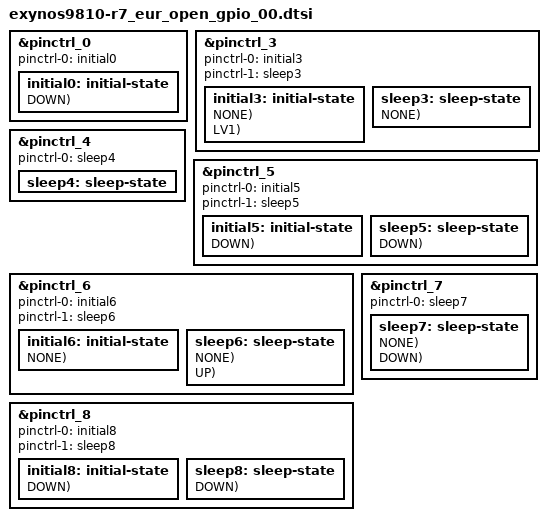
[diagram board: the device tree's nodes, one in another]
/*
 * Copyright (c) 2016 Samsung Electronics Co., Ltd.
 *		http://www.samsung.com
 *
 * This program is free software; you can redistribute it and/or modify
 * it under the terms of the GNU General Public License version 2 as
 * published by the Free Software Foundation.
 */

// Support R7 EUR HW REV0.0 (0 0000)

#include "exynos_gpio_config_macros.dtsi"

/*
 * pin banks of exynos9810 pin-controller 0 (ALIVE)
 * ETC1
 * GPA0 GPA1 GPA2 GPA3
 * GPQ0
 * GPA4
 * Note that do not set sleep state because GPA0/1/2/3/4, GPQ0 and ETC1 are in
 * ALIVE region.
 */
&pinctrl_0 {
	pinctrl-names = "default";
	pinctrl-0 = <&initial0>;
	initial0: initial-state {
		PIN_IN(gpq0-5, DOWN);	/* NC */
	};
};

/*
 * pin banks of exynos9810 pin-controller 1 (AUD)
 * GPB0 GPB1 GPB2
 * Do not set!! Audio block is very sensitive!!
 */

/*
 * pin banks of exynos9810 pin-controller 3 (CMGP)
 * GPM0 GPM1 GPM2 GPM3 GPM4 GPM5 GPM6 GPM7
 * GPM10 GPM11 GPM12 GPM13 GPM14 GPM15 GPM16 GPM17
 * GPM40 GPM41 GPM42 GPM43
 */
&pinctrl_3 {
	pinctrl-names = "default","sleep";
	pinctrl-0 = <&initial3>;
	pinctrl-1 = <&sleep3>;
	initial3: initial-state {
		PIN_FUNC(gpm4-0, 2, NONE);	/* SHUB_CP_TXD */
		PIN_FUNC(gpm5-0, 2, NONE);	/* SHUB_CP_RXD */
		PIN_OUT_SET(gpm42-0, 1, LV1);    /* SPEN_LDO_EN */
	};
	sleep3: sleep-state {
		PIN_SLP(gpm42-0, PREV, NONE);    /* SPEN_LDO_EN */
	};
};

/*
 * pin banks of exynos9810 pin-controller 4 (FSYS0)
 * GPF0
 */
&pinctrl_4 {
	pinctrl-names = "sleep";
	pinctrl-0 = <&sleep4>;
	sleep4: sleep-state {

	};
};

/*
 * pin banks of exynos9810 pin-controller 5 (FSYS1)
 * GPF1 GPF2
 */
&pinctrl_5 {
	pinctrl-names = "default","sleep";
	pinctrl-0 = <&initial5>;
	pinctrl-1 = <&sleep5>;
	initial5: initial-state {
		PIN_IN(gpf2-1, DOWN);		/* NC */
		PIN_IN(gpf2-4, DOWN);		/* NC */
	};
	sleep5: sleep-state {
		PIN_SLP(gpf2-1, INPUT, DOWN);	/* NC */
		PIN_SLP(gpf2-4, INPUT, DOWN);	/* NC */
	};
};

/*
 * pin banks of exynos9810 pin-controller 6 (PERIC0)
 * GPP0 GPP1 GPP2 GPP3
 * GPG0 GPG1 GPG2
 */
&pinctrl_6 {
	pinctrl-names = "default","sleep";
	pinctrl-0 = <&initial6>;
	pinctrl-1 = <&sleep6>;
	initial6: initial-state {
		PIN_IN(gpp2-4, NONE);	/* MEM_SCL_1P8 */
		PIN_IN(gpp2-5, NONE);	/* MEM_SDA_1P8 */

		PIN_IN(gpg1-1, NONE);	/* HW_REV_M */
		PIN_IN(gpg1-2, NONE);	/* HW_REV3 */
		PIN_IN(gpg1-3, NONE);	/* HW_REV2 */
		PIN_IN(gpg1-4, NONE);	/* HW_REV1 */
		PIN_IN(gpg1-5, NONE);	/* HW_REV0 */
	};
	sleep6: sleep-state {
		PIN_SLP(gpp2-4, INPUT, NONE);	/* MEM_SCL_1P8 */
		PIN_SLP(gpp2-5, INPUT, NONE);	/* MEM_SDA_1P8 */

		PIN_SLP(gpp1-4, PREV, NONE);	/* TSP_SCL_1P8 */
		PIN_SLP(gpp1-5, PREV, NONE);	/* TSP_SDA_1P8 */

		PIN_SLP(gpg0-0, INPUT, UP);	/* FG_ALERT_N */
		PIN_SLP(gpg0-3, INPUT, NONE);	/* SMPL_WARN_AP */

		PIN_SLP(gpg1-1, INPUT, NONE);	/* HW_REV_M */
		PIN_SLP(gpg1-2, INPUT, NONE);	/* HW_REV3 */
		PIN_SLP(gpg1-3, INPUT, NONE);	/* HW_REV2 */
		PIN_SLP(gpg1-4, INPUT, NONE);	/* HW_REV1 */
		PIN_SLP(gpg1-5, INPUT, NONE);	/* HW_REV0 */

		PIN_SLP(gpg1-7, PREV, NONE);	/* DC_IRQ_N */

		PIN_SLP(gpg2-4, PREV, NONE);	/* TORCH */
	};
};

/*
 * pin banks of exynos9810 pin-controller 7 (PERIC1)
 * GPP4 GPP5 GPP6
 * GPC0 GPC1
 * GPD0
 * GPG3
 */
&pinctrl_7 {
	pinctrl-names = "sleep";
	pinctrl-0 = <&sleep7>;
	sleep7:sleep-state {
		PIN_SLP(gpd0-2, OUT0, NONE);	/* XBOOTLDO0 */

		PIN_SLP(gpp4-4, INPUT, NONE);	/* SPK_AMP_SCL_1P8 */
		PIN_SLP(gpp4-5, INPUT, NONE);	/* SPK_AMP_SDA_1P8 */

		PIN_SLP(gpp4-6, INPUT, DOWN);	/* NC */
		PIN_SLP(gpp4-7, INPUT, DOWN);	/* NC */
		
		PIN_SLP(gpp5-6, PREV, NONE);	/* SPEN_SDA_1P8 */
		PIN_SLP(gpp5-7, PREV, NONE);	/* SPEN_SCL_1P8 */
	};
};

/*
 * pin banks of exynos9810 pin-controller 8
 * GPT0
 */
&pinctrl_8 {
	pinctrl-names = "default","sleep";
	pinctrl-0 = <&initial8>;
	pinctrl-1 = <&sleep8>;
	initial8: initial-state {
		PIN_IN(gpt0-0, DOWN);		/* NC */
		PIN_IN(gpt0-1, DOWN);		/* NC */
		PIN_IN(gpt0-2, DOWN);		/* NC */
	};
	sleep8: sleep-state {
		PIN_SLP(gpt0-0, INPUT, DOWN);	/* NC */
		PIN_SLP(gpt0-1, INPUT, DOWN);	/* NC */
		PIN_SLP(gpt0-2, INPUT, DOWN);	/* NC */
	};
};

